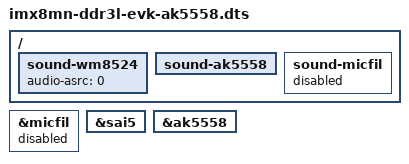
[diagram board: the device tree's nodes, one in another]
/*
 * Copyright 2020 NXP
 *
 * This program is free software; you can redistribute it and/or
 * modify it under the terms of the GNU General Public License
 * as published by the Free Software Foundation; either version 2
 * of the License, or (at your option) any later version.
 *
 * This program is distributed in the hope that it will be useful,
 * but WITHOUT ANY WARRANTY; without even the implied warranty of
 * MERCHANTABILITY or FITNESS FOR A PARTICULAR PURPOSE.  See the
 * GNU General Public License for more details.
 */

#include "imx8mn-ddr3l-evk.dts"

/ {
	sound-wm8524 {
		audio-asrc = <0>;
	};
	sound-ak5558 {
		status = "okay";
	};
	sound-micfil {
		status = "disabled";
	};
};

&micfil {
	status = "disabled";
};

&sai5 {
	status = "okay";
};

&ak5558 {
	status = "okay";
};
